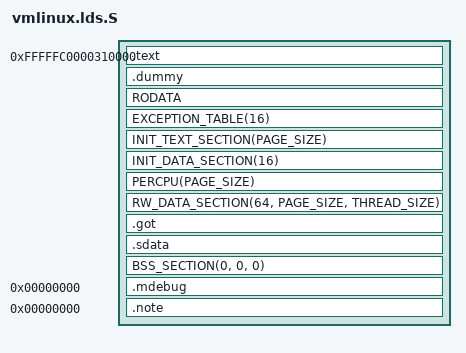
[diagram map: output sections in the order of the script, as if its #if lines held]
/* Copyright Statement:
 *
 * This software/firmware and related documentation ("MediaTek Software") are
 * protected under relevant copyright laws. The information contained herein
 * is confidential and proprietary to MediaTek Inc. and/or its licensors.
 * Without the prior written permission of MediaTek inc. and/or its licensors,
 * any reproduction, modification, use or disclosure of MediaTek Software,
 * and information contained herein, in whole or in part, shall be strictly prohibited.
 *
 * MediaTek Inc. (C) 2010. All rights reserved.
 *
 * BY OPENING THIS FILE, RECEIVER HEREBY UNEQUIVOCALLY ACKNOWLEDGES AND AGREES
 * THAT THE SOFTWARE/FIRMWARE AND ITS DOCUMENTATIONS ("MEDIATEK SOFTWARE")
 * RECEIVED FROM MEDIATEK AND/OR ITS REPRESENTATIVES ARE PROVIDED TO RECEIVER ON
 * AN "AS-IS" BASIS ONLY. MEDIATEK EXPRESSLY DISCLAIMS ANY AND ALL WARRANTIES,
 * EXPRESS OR IMPLIED, INCLUDING BUT NOT LIMITED TO THE IMPLIED WARRANTIES OF
 * MERCHANTABILITY, FITNESS FOR A PARTICULAR PURPOSE OR NONINFRINGEMENT.
 * NEITHER DOES MEDIATEK PROVIDE ANY WARRANTY WHATSOEVER WITH RESPECT TO THE
 * SOFTWARE OF ANY THIRD PARTY WHICH MAY BE USED BY, INCORPORATED IN, OR
 * SUPPLIED WITH THE MEDIATEK SOFTWARE, AND RECEIVER AGREES TO LOOK ONLY TO SUCH
 * THIRD PARTY FOR ANY WARRANTY CLAIM RELATING THERETO. RECEIVER EXPRESSLY ACKNOWLEDGES
 * THAT IT IS RECEIVER'S SOLE RESPONSIBILITY TO OBTAIN FROM ANY THIRD PARTY ALL PROPER LICENSES
 * CONTAINED IN MEDIATEK SOFTWARE. MEDIATEK SHALL ALSO NOT BE RESPONSIBLE FOR ANY MEDIATEK
 * SOFTWARE RELEASES MADE TO RECEIVER'S SPECIFICATION OR TO CONFORM TO A PARTICULAR
 * STANDARD OR OPEN FORUM. RECEIVER'S SOLE AND EXCLUSIVE REMEDY AND MEDIATEK'S ENTIRE AND
 * CUMULATIVE LIABILITY WITH RESPECT TO THE MEDIATEK SOFTWARE RELEASED HEREUNDER WILL BE,
 * AT MEDIATEK'S OPTION, TO REVISE OR REPLACE THE MEDIATEK SOFTWARE AT ISSUE,
 * OR REFUND ANY SOFTWARE LICENSE FEES OR SERVICE CHARGE PAID BY RECEIVER TO
 * MEDIATEK FOR SUCH MEDIATEK SOFTWARE AT ISSUE.
 */

#include <asm-generic/vmlinux.lds.h>
#include <asm/thread_info.h>
#include <asm/page.h>

OUTPUT_FORMAT("elf64-alpha")
OUTPUT_ARCH(alpha)
ENTRY(__start)
PHDRS { kernel PT_LOAD; note PT_NOTE; }
jiffies = jiffies_64;
SECTIONS
{
#ifdef CONFIG_ALPHA_LEGACY_START_ADDRESS
	. = 0xfffffc0000310000;
#else
	. = 0xfffffc0001010000;
#endif

	_text = .;	/* Text and read-only data */
	.text : {
		HEAD_TEXT
		TEXT_TEXT
		SCHED_TEXT
		LOCK_TEXT
		*(.fixup)
		*(.gnu.warning)
	} :kernel
	_etext = .;	/* End of text section */

	NOTES :kernel :note
	.dummy : {
		*(.dummy)
	} :kernel

	RODATA
	EXCEPTION_TABLE(16)

	/* Will be freed after init */
	__init_begin = ALIGN(PAGE_SIZE);
	INIT_TEXT_SECTION(PAGE_SIZE)
	INIT_DATA_SECTION(16)
	PERCPU(PAGE_SIZE)
	/* Align to THREAD_SIZE rather than PAGE_SIZE here so any padding page
	   needed for the THREAD_SIZE aligned init_task gets freed after init */
	. = ALIGN(THREAD_SIZE);
	__init_end = .;
	/* Freed after init ends here */

	_data = .;
	RW_DATA_SECTION(64, PAGE_SIZE, THREAD_SIZE)

	.got : {
		*(.got)
	}
	.sdata : {
		*(.sdata)
	}
	_edata = .;	/* End of data section */

	BSS_SECTION(0, 0, 0)
	_end = .;

	.mdebug 0 : {
		*(.mdebug)
	}
	.note 0 : {
		*(.note)
	}

	STABS_DEBUG
	DWARF_DEBUG

	DISCARDS
}
